AUTOSAR XML (schema 00049)
package /AdaptiveApplicationSwComponents
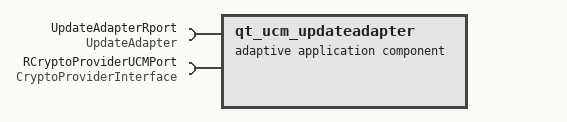
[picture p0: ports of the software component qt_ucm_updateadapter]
  adaptive application sw component type qt_ucm_updateadapter: category=APPLICATION_LEVEL
    require port UpdateAdapterRport: required-interface=UpdateAdapter
    require port RCryptoProviderUCMPort: required-interface=CryptoProviderInterface
